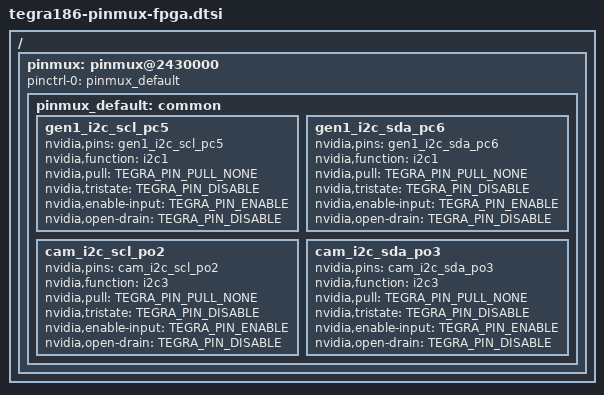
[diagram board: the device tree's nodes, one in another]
/*
 * Copyright (c) 2015, NVIDIA CORPORATION.  All rights reserved.
 *
 * This program is free software; you can redistribute it and/or modify
 * it under the terms of the GNU General Public License as published by
 * the Free Software Foundation; either version 2 of the License, or
 * (at your option) any later version.
 *
 * This program is distributed in the hope that it will be useful, but WITHOUT
 * ANY WARRANTY; without even the implied warranty of MERCHANTABILITY or
 * FITNESS FOR A PARTICULAR PURPOSE.  See the GNU General Public License for
 * more details.
 *
 * You should have received a copy of the GNU General Public License along
 * with this program; if not, write to the Free Software Foundation, Inc.,
 * 51 Franklin Street, Fifth Floor, Boston, MA  02110-1301, USA.
 */

#include <dt-bindings/pinctrl/pinctrl-tegra.h>

/ {

	pinmux: pinmux@2430000 {
		status = "okay";
		pinctrl-names = "default";
		pinctrl-0 = <&pinmux_default>;

		pinmux_default: common {
		/* SFIO Pin Configuration */
			gen1_i2c_scl_pc5 {
				nvidia,pins = "gen1_i2c_scl_pc5";
				nvidia,function = "i2c1";
				nvidia,pull = <TEGRA_PIN_PULL_NONE>;
				nvidia,tristate = <TEGRA_PIN_DISABLE>;
				nvidia,enable-input = <TEGRA_PIN_ENABLE>;
				nvidia,open-drain = <TEGRA_PIN_DISABLE>;
			};
			gen1_i2c_sda_pc6 {
				nvidia,pins = "gen1_i2c_sda_pc6";
				nvidia,function = "i2c1";
				nvidia,pull = <TEGRA_PIN_PULL_NONE>;
				nvidia,tristate = <TEGRA_PIN_DISABLE>;
				nvidia,enable-input = <TEGRA_PIN_ENABLE>;
				nvidia,open-drain = <TEGRA_PIN_DISABLE>;
			};
			cam_i2c_scl_po2 {
				nvidia,pins = "cam_i2c_scl_po2";
				nvidia,function = "i2c3";
				nvidia,pull = <TEGRA_PIN_PULL_NONE>;
				nvidia,tristate = <TEGRA_PIN_DISABLE>;
				nvidia,enable-input = <TEGRA_PIN_ENABLE>;
				nvidia,open-drain = <TEGRA_PIN_DISABLE>;
			};
			cam_i2c_sda_po3 {
				nvidia,pins = "cam_i2c_sda_po3";
				nvidia,function = "i2c3";
				nvidia,pull = <TEGRA_PIN_PULL_NONE>;
				nvidia,tristate = <TEGRA_PIN_DISABLE>;
				nvidia,enable-input = <TEGRA_PIN_ENABLE>;
				nvidia,open-drain = <TEGRA_PIN_DISABLE>;
			};
		};
	};
};
